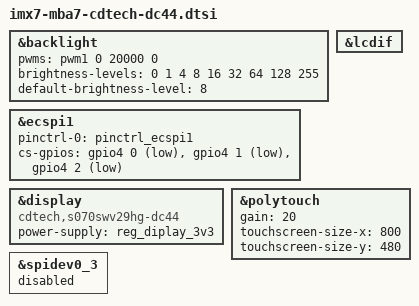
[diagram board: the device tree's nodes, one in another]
// SPDX-License-Identifier: (GPL-2.0-or-later OR MIT)
/*
 * Copyright (c) 2016-2023 TQ-Systems GmbH <linux@ew.tq-group.com>,
 * D-82229 Seefeld, Germany.
 * Author: Marco Felsch
 * Author: Markus Niebel <Markus.Niebel@tq-group.com>
 */

&backlight {
	pwms = <&pwm1 0 20000 0>; /* 50 kHz */
	brightness-levels = <0 1 4 8 16 32 64 128 255>;
	default-brightness-level = <8>;
	status = "okay";
};

&ecspi1 {
	pinctrl-names = "default";
	/* SS0 is shared with touch IRQ, remove it here */
	pinctrl-0 = <&pinctrl_ecspi1>;
	cs-gpios = <&gpio4 0 GPIO_ACTIVE_LOW>, <&gpio4 1 GPIO_ACTIVE_LOW>,
		   <&gpio4 2 GPIO_ACTIVE_LOW>;
};

&lcdif {
	status = "okay";
};

&display {
	compatible = "cdtech,s070swv29hg-dc44";
	power-supply = <&reg_diplay_3v3>;
};

&polytouch {
	gain = <20>;

	touchscreen-size-x = <800>;
	touchscreen-size-y = <480>;

	status = "okay";
};

&spidev0_3 {
	status = "disabled";
};
